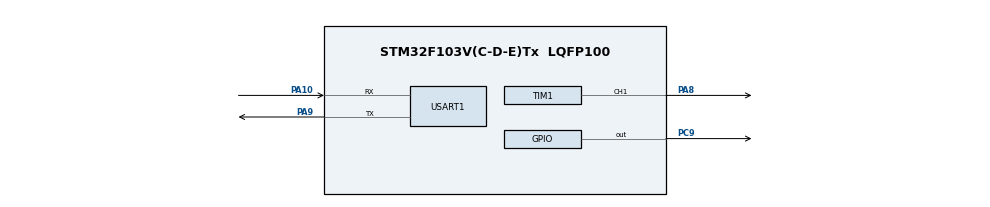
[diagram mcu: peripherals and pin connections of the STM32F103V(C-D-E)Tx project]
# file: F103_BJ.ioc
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Dma.Request0=TIM1_CH1
Dma.TIM1_CH1.0.Direction=DMA_PERIPH_TO_MEMORY
Dma.TIM1_CH1.0.Instance=DMA1_Channel2
Dma.TIM1_CH1.0.MemDataAlignment=DMA_MDATAALIGN_HALFWORD
Dma.TIM1_CH1.0.MemInc=DMA_MINC_DISABLE
Dma.TIM1_CH1.0.Mode=DMA_NORMAL
Dma.TIM1_CH1.0.PeriphDataAlignment=DMA_PDATAALIGN_HALFWORD
Dma.TIM1_CH1.0.PeriphInc=DMA_PINC_ENABLE
Dma.TIM1_CH1.0.Priority=DMA_PRIORITY_LOW
Mcu.Family=STM32F1
Mcu.Name=STM32F103V(C-D-E)Tx
Mcu.Package=LQFP100
NVIC.DMA1_Channel2_IRQn=true\:0\:0\:false\:false\:true\:false\:true
NVIC.PriorityGroup=NVIC_PRIORITYGROUP_4
NVIC.USART1_IRQn=true\:2\:0\:true\:false\:true\:true\:true
OSC_IN.Mode=HSE-External-Oscillator
OSC_IN.Signal=RCC_OSC_IN
OSC_OUT.Mode=HSE-External-Oscillator
OSC_OUT.Signal=RCC_OSC_OUT
PA10.Mode=Asynchronous
PA10.Signal=USART1_RX
PA13.Mode=Serial_Wire
PA13.Signal=SYS_JTMS-SWDIO
PA14.Mode=Serial_Wire
PA14.Signal=SYS_JTCK-SWCLK
PA8.Signal=S_TIM1_CH1
PA9.Mode=Asynchronous
PA9.Signal=USART1_TX
PC9.Signal=GPIO_Output
ProjectManager.HeapSize=0x200
ProjectManager.StackSize=0x400
ProjectManager.TargetToolchain=MDK-ARM V5.27
RCC.APB1Freq_Value=8000000
RCC.APB2Freq_Value=8000000
SH.S_TIM1_CH1.0=TIM1_CH1,PWM Generation1 CH1
TIM1.Channel-PWM\ Generation1\ CH1=TIM_CHANNEL_1
TIM1.Period=999
TIM1.Prescaler=71
USART1.VirtualMode=VM_ASYNC
board=custom

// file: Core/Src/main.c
/* USER CODE BEGIN Header */
/**
  ******************************************************************************
  * @file           : main.c
  * @brief          : Main program body
  ******************************************************************************
  * @attention
  *
  * <h2><center>&copy; Copyright (c) 2023 STMicroelectronics.
  * All rights reserved.</center></h2>
  *
  * This software component is licensed by ST under BSD 3-Clause license,
  * the "License"; You may not use this file except in compliance with the
  * License. You may obtain a copy of the License at:
  *                        opensource.org/licenses/BSD-3-Clause
  *
  ******************************************************************************
  */
/* USER CODE END Header */
#include "main.h"
#include "dma.h"
#include "tim.h"
#include "usart.h"
#include "gpio.h"

/* USER CODE BEGIN PV */
uint16_t pwm_ccr[100];
/* USER CODE END PV */

void SystemClock_Config(void);

/* USER CODE BEGIN 0 */
void HAL_TIM_PWM_PulseFinishedCallback(TIM_HandleTypeDef *htim)
{

    __HAL_TIM_SetCompare(&htim1, TIM_CHANNEL_1,0); //ռ�ձ���0��������ᵼ�µ�����ɫ����
    HAL_TIM_PWM_Stop_DMA(&htim1,TIM_CHANNEL_1);
}
/* USER CODE END 0 */

int main(void)
{

  /* MCU Configuration--------------------------------------------------------*/

  /* Reset of all peripherals, Initializes the Flash interface and the Systick. */
  HAL_Init();

  /* Configure the system clock */
  SystemClock_Config();

  /* Initialize all configured peripherals */
  MX_GPIO_Init();
  MX_DMA_Init();
  MX_TIM1_Init();
  MX_USART1_UART_Init();
  /* USER CODE BEGIN 2 */
  for(int i=0;i<1000;i++)
    {
        pwm_ccr[i]=i*10+10;
    }
    HAL_TIM_PWM_Start_DMA(&htim1,TIM_CHANNEL_1,(uint32_t*)pwm_ccr, 1000);
  /* USER CODE END 2 */

  /* Infinite loop */
  while (1)
  {

  }
}

void SystemClock_Config(void)
{
  RCC_OscInitTypeDef RCC_OscInitStruct = {0};
  RCC_ClkInitTypeDef RCC_ClkInitStruct = {0};

  /** Initializes the RCC Oscillators according to the specified parameters
  * in the RCC_OscInitTypeDef structure.
  */
  RCC_OscInitStruct.OscillatorType = RCC_OSCILLATORTYPE_HSI;
  RCC_OscInitStruct.HSIState = RCC_HSI_ON;
  RCC_OscInitStruct.HSICalibrationValue = RCC_HSICALIBRATION_DEFAULT;
  RCC_OscInitStruct.PLL.PLLState = RCC_PLL_NONE;
  if (HAL_RCC_OscConfig(&RCC_OscInitStruct) != HAL_OK)
  {
    Error_Handler();
  }
  /** Initializes the CPU, AHB and APB buses clocks
  */
  RCC_ClkInitStruct.ClockType = RCC_CLOCKTYPE_HCLK|RCC_CLOCKTYPE_SYSCLK
                              |RCC_CLOCKTYPE_PCLK1|RCC_CLOCKTYPE_PCLK2;
  RCC_ClkInitStruct.SYSCLKSource = RCC_SYSCLKSOURCE_HSI;
  RCC_ClkInitStruct.AHBCLKDivider = RCC_SYSCLK_DIV1;
  RCC_ClkInitStruct.APB1CLKDivider = RCC_HCLK_DIV1;
  RCC_ClkInitStruct.APB2CLKDivider = RCC_HCLK_DIV1;

  if (HAL_RCC_ClockConfig(&RCC_ClkInitStruct, FLASH_LATENCY_0) != HAL_OK)
  {
    Error_Handler();
  }
}

void Error_Handler(void)
{
  __disable_irq();
  while (1)
  {
  }
}

/************************ (C) COPYRIGHT STMicroelectronics *****END OF FILE****/
